# RZT2L register map
Vendor: Renesas Electronics Corporation; Series: RZT; File version: 1.20.00
CPU: other r0p0, little endian, MPU, no FPU, VTOR, 4 interrupt priority bits, 624 interrupts
Registers are 32-bit, read-write, reset 0x0 unless marked. A register's access mark holds for its fields unless they carry their own. Offsets are from the block's base; [hi:lo] are bit positions; {n}, {i} and the like mark numbered series; 'fields as' and 'values as' point back to an identical list.

## ICU — Interrupt Controller
Base 0x81048000
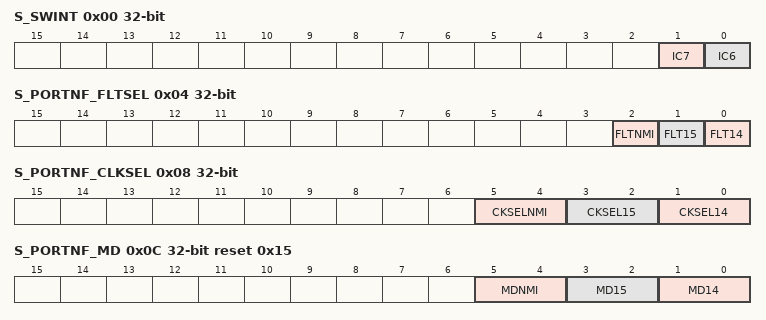
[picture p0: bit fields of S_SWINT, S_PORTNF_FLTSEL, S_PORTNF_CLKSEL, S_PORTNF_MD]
0x00 S_SWINT wo — Software Interrupt Register for Safety Register
  [1] IC7 — Software Interrupt register
  [0] IC6 — Software Interrupt register
0x04 S_PORTNF_FLTSEL — Interrupt Noise Filter Enable Register for Safety Register
  [all] fields
    0=Disable; 1=Enable
  [2] FLTNMI — Noise filter enable for NMI
  [1] FLT15 — Noise filter enable for IRQ15
  [0] FLT14 — Noise filter enable for IRQ14
0x08 S_PORTNF_CLKSEL — Interrupt Noise Filter Setting Register for Safety Register
  [all] fields
    0=Divided by 1; 1=Divided by 8; 2=Divided by 32; 3=Divided by 64
  [5:4] CKSELNMI — Select noise filter sampling frequency dividend rate for NMI.
  [3:2] CKSEL15 — Select noise filter sampling frequency dividend rate for IRQ15.
  [1:0] CKSEL14 — Select noise filter sampling frequency dividend rate for IRQ14.
0x0C S_PORTNF_MD reset 0x15 — Interrupt Edge Detection Setting Register for Safety Register
  [5:4] MDNMI — Select detection mode for NMI
    0=Invert; 1=Falling edge; 2=Rising edge; 3=Falling and rising edges
  [3:2] MD15 — Select detection mode for IRQ15
    0=Low level; 1=Falling edge; 2=Rising edge; 3=Falling and rising edges
  [1:0] MD14 — Select detection mode for IRQ14
    values as MD15
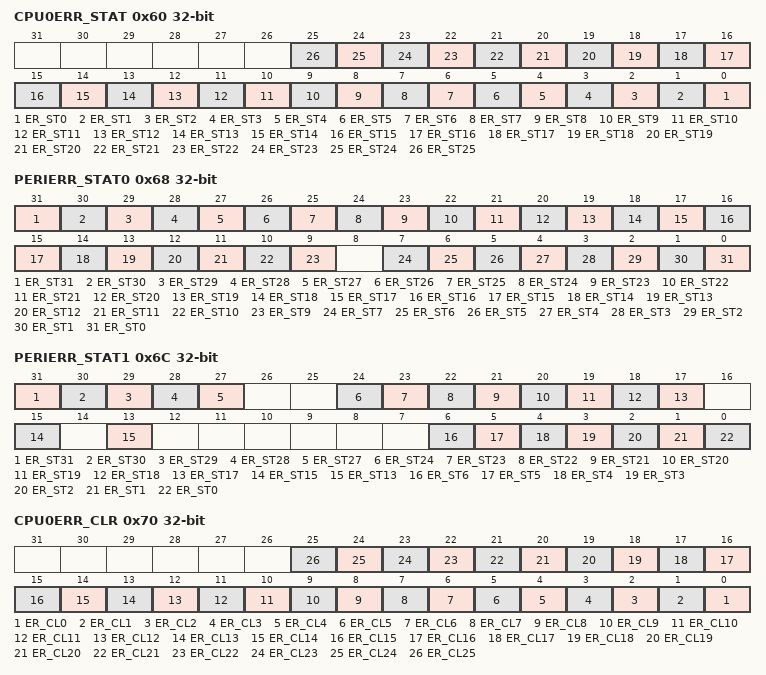
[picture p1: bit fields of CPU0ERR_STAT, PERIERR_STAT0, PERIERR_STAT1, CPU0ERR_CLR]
0x60 CPU0ERR_STAT ro — CPU0 Error Event Status Register
  [all] fields
    0=No error; 1=Error occurred
  [n] ER_ST{n} (n=0..25) — Indicate captured error status for CPU0_ERREVENT{n}
0x68 PERIERR_STAT0 ro — Peripheral Error Event Status Register 0
  [all] fields
    0=No error; 1=Error occurred
  [31] ER_ST31 — Indicate captured error status for DSMIF1_SCDE2
  [30] ER_ST30 — Indicate captured error status for DSMIF1_SCDE1
  [29] ER_ST29 — Indicate captured error status for DSMIF1_SCDE0
  [28] ER_ST28 — Indicate captured error status for DSMIF1_OVC2EHn (n = 0 to 2)
  [27] ER_ST27 — Indicate captured error status for DSMIF1_OVC1EHn (n = 0 to 2)
  [26] ER_ST26 — Indicate captured error status for DSMIF1_OVC0EHn (n = 0 to 2)
  [25] ER_ST25 — Indicate captured error status for DSMIF1_OVC2ELn (n = 0 to 2)
  [24] ER_ST24 — Indicate captured error status for DSMIF1_OVC1ELn (n = 0 to 2)
  [23] ER_ST23 — Indicate captured error status for DSMIF1_OVC0ELn (n = 0 to 2)
  [22] ER_ST22 — Indicate captured error status for DSMIF1_UTCSE
  [21] ER_ST21 — Indicate captured error status for DSMIF1_LTCSE
  [20] ER_ST20 — Indicate captured error status for DSMIF0_SCDE2
  [19] ER_ST19 — Indicate captured error status for DSMIF0_SCDE1
  [18] ER_ST18 — Indicate captured error status for DSMIF0_SCDE0
  [17] ER_ST17 — Indicate captured error status for DSMIF0_OVC2EHn (n = 0 to 2)
  [16] ER_ST16 — Indicate captured error status for DSMIF0_OVC1EHn (n = 0 to 2)
  [15] ER_ST15 — Indicate captured error status for DSMIF0_OVC0EHn (n = 0 to 2)
  [14] ER_ST14 — Indicate captured error status for DSMIF0_OVC2ELn (n = 0 to 2)
  [13] ER_ST13 — Indicate captured error status for DSMIF0_OVC1ELn (n = 0 to 2)
  [12] ER_ST12 — Indicate captured error status for DSMIF0_OVC0ELn (n = 0 to 2)
  [11] ER_ST11 — Indicate captured error status for DSMIF0_UTCSE
  [10] ER_ST10 — Indicate captured error status for DSMIF0_LTCSE
  [9] ER_ST9 — Indicate captured error status for USB_FDMAERR
  [7] ER_ST7 — Indicate captured error status for WDT_NMIUNDF0
  [6] ER_ST6 — Indicate captured error status for DMAC1_ERR
  [5] ER_ST5 — Indicate captured error status for DMAC0_ERR
  [4] ER_ST4 — Indicate captured error status for BSC_WTO
  [3] ER_ST3 — Indicate captured error status for CLMA2_INT
  [2] ER_ST2 — Indicate captured error status for CLMA1_INT
  [1] ER_ST1 — Indicate captured error status for CLMA0_INT
  [0] ER_ST0 — Indicate captured error status for CLMA3_INT
0x6C PERIERR_STAT1 ro — Peripheral Error Event Status Register 1
  [all] fields
    0=No error; 1=Error occurred
  [31] ER_ST31 — Indicate capture error status for DSMIF0_OVC2EL0
  [30] ER_ST30 — Indicate capture error status for DSMIF0_OVC1EH0
  [29] ER_ST29 — Indicate capture error status for DSMIF0_OVC1EL0
  [28] ER_ST28 — Indicate captured error status for MPU_DBGW
  [27] ER_ST27 — Indicate captured error status for MPU_DBGR
  [24] ER_ST24 — Indicate captured error status for MPU_USBF
  [23] ER_ST23 — Indicate captured error status for MPU_USBH
  [22] ER_ST22 — Indicate captured error status for MPU_GMACW
  [21] ER_ST21 — Indicate captured error status for MPU_GMACR
  [20] ER_ST20 — Indicate captured error status for MPU_DMACW1
  [19] ER_ST19 — Indicate captured error status for MPU_DMACR1
  [18] ER_ST18 — Indicate captured error status for MPU_DMACW0
  [17] ER_ST17 — Indicate captured error status for MPU_DMACR0
  [15] ER_ST15 — Indicate captured error status for MPU_SHOSTIF
  [13] ER_ST13 — Indicate captured error status for MAIN_BUS_ERRINT
  [6] ER_ST6 — Indicate captured error status for SRAM1_OVF
  [5] ER_ST5 — Indicate captured error status for SRAM1_IE2
  [4] ER_ST4 — Indicate captured error status for SRAM1_IE1
  [3] ER_ST3 — Indicate captured error status for SRAM0_OVF
  [2] ER_ST2 — Indicate captured error status for SRAM0_IE2
  [1] ER_ST1 — Indicate captured error status for SRAM0_IE1
  [0] ER_ST0 — Indicate captured error status for DOC_DOPCI
0x70 CPU0ERR_CLR wo — CPU0 Error Event Status Clear Register
  [n] ER_CL{n} (n=0..25) — Clear captured error status for CPU0ERR_STAT register by writing 1
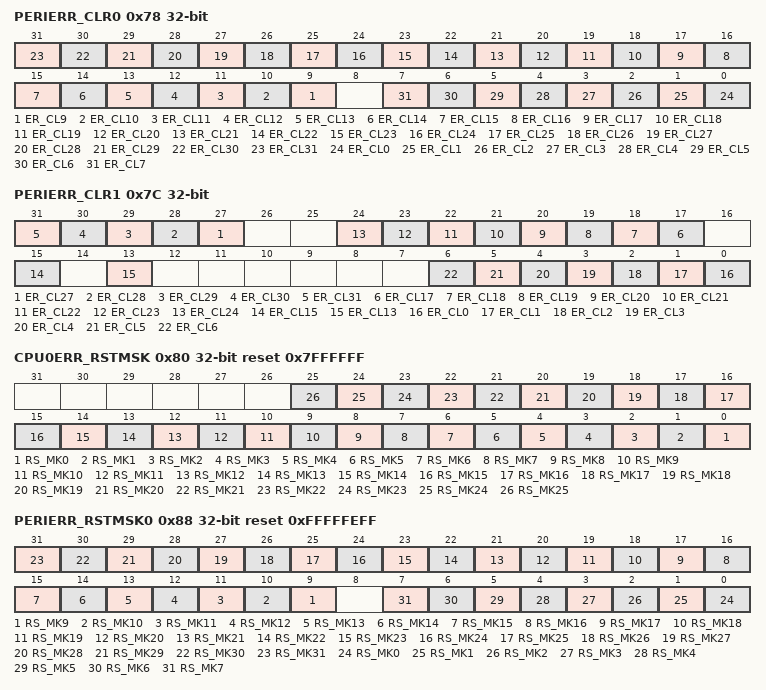
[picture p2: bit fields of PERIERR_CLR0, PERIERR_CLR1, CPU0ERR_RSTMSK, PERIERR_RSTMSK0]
0x78 PERIERR_CLR0 wo — Peripheral Error Event Status Clear Register 0
  [n] ER_CL{n} (n=9..31) — Clear captured error status for PERIERR_STAT0 register by writing 1
  [n] ER_CL{n} (n=0..7) — Clear captured error status for PERIERR_STAT0 register by writing 1
0x7C PERIERR_CLR1 wo — Peripheral Error Event Status Clear Register 1
  [n] ER_CL{n} (n=27..31) — Clear captured error status for PERIERR_STAT1 register by writing 1
  [n] ER_CL{n} (n=17..24) — Clear captured error status for PERIERR_STAT1 register by writing 1
  [15] ER_CL15 — Clear captured error status for PERIERR_STAT1 register by writing 1
  [13] ER_CL13 — Clear captured error status for PERIERR_STAT1 register by writing 1
  [n] ER_CL{n} (n=0..6) — Clear captured error status for PERIERR_STAT1 register by writing 1
0x80 CPU0ERR_RSTMSK reset 0x7FFFFFF — CPU0 Error Event Reset Mask Register
  [all] fields
    0=Release; 1=Mask
  [n] RS_MK{n} (n=0..25) — Mask captured error status as a reset event for CPU0ERR_STAT
0x88 PERIERR_RSTMSK0 reset 0xFFFFFEFF — Peripheral Error Event Reset Mask Register 0
  [all] fields
    0=Release; 1=Mask
  [n] RS_MK{n} (n=9..31) — Mask captured error status as a reset event for PERIERR_STAT0
  [n] RS_MK{n} (n=0..7) — Mask captured error status as a reset event for PERIERR_STAT0
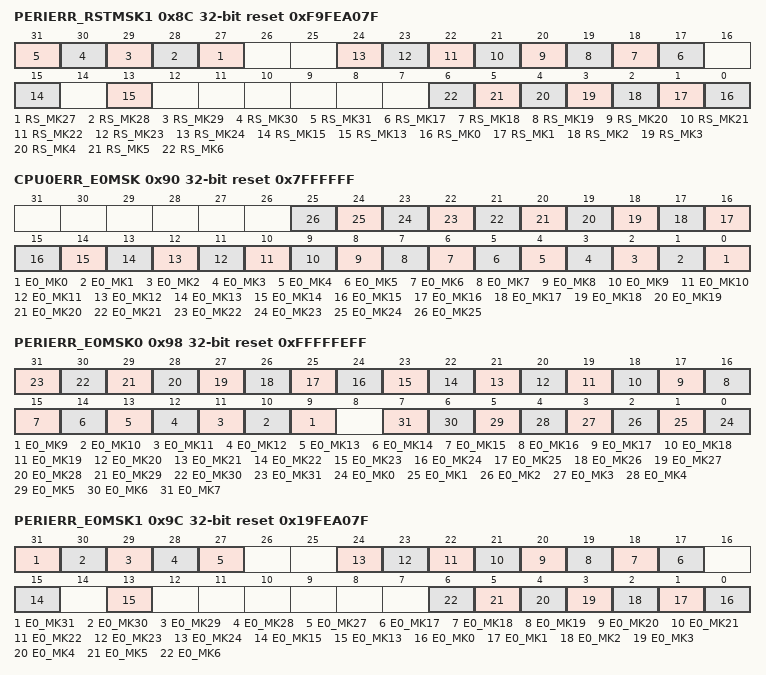
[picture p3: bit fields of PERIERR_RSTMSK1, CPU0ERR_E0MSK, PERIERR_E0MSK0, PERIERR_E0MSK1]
0x8C PERIERR_RSTMSK1 reset 0xF9FEA07F — Peripheral Error Event Reset Mask Register 1
  [all] fields
    0=Release; 1=Mask
  [n] RS_MK{n} (n=27..31) — Mask captured error status as a reset event for PERIERR_STAT1
  [n] RS_MK{n} (n=17..24) — Mask captured error status as a reset event for PERIERR_STAT1
  [15] RS_MK15 — Mask captured error status as a reset event for PERIERR_STAT1
  [13] RS_MK13 — Mask captured error status as a reset event for PERIERR_STAT1
  [n] RS_MK{n} (n=0..6) — Mask captured error status as a reset event for PERIERR_STAT1
0x90 CPU0ERR_E0MSK reset 0x7FFFFFF — CPU0 E0 Error Event Mask Register
  [all] fields
    0=Release; 1=Mask
  [n] E0_MK{n} (n=0..25) — Mask captured error status as a CPU0_ERR0 event for CPU0ERR_STAT
0x98 PERIERR_E0MSK0 reset 0xFFFFFEFF — Peripheral E0 Error Event Mask Register 0
  [all] fields
    0=Release; 1=Mask
  [n] E0_MK{n} (n=9..31) — Mask captured error status as a PERI_ERR0 event for PERIERR_STAT0
  [n] E0_MK{n} (n=0..7) — Mask captured error status as a PERI_ERR0 event for PERIERR_STAT0
0x9C PERIERR_E0MSK1 reset 0x19FEA07F — Peripheral E0 Error Event Mask Register 1
  [all] fields
    0=Release; 1=Mask
  [31] E0_MK31 — Mask captured error status as a PERI_ERR0 event for PERIERR_STAT1
  [30] E0_MK30 — Mask captured error status as a PERI_ERR0 event for PERIERR_STAT1
  [29] E0_MK29 — Mask capture error status as a PERI_ERR0 event for PERIERR_STAT1
  [28] E0_MK28 — Mask captured error status as a PERI_ERR0 event for PERIERR_STAT1
  [27] E0_MK27 — Mask captured error status as a PERI_ERR0 event for PERIERR_STAT1
  [n] E0_MK{n} (n=17..24) — Mask captured error status as a PERI_ERR0 event for PERIERR_STAT1
  [15] E0_MK15 — Mask captured error status as a PERI_ERR0 event for PERIERR_STAT1
  [13] E0_MK13 — Mask captured error status as a PERI_ERR0 event for PERIERR_STAT1
  [n] E0_MK{n} (n=0..6) — Mask captured error status as a PERI_ERR0 event for PERIERR_STAT1
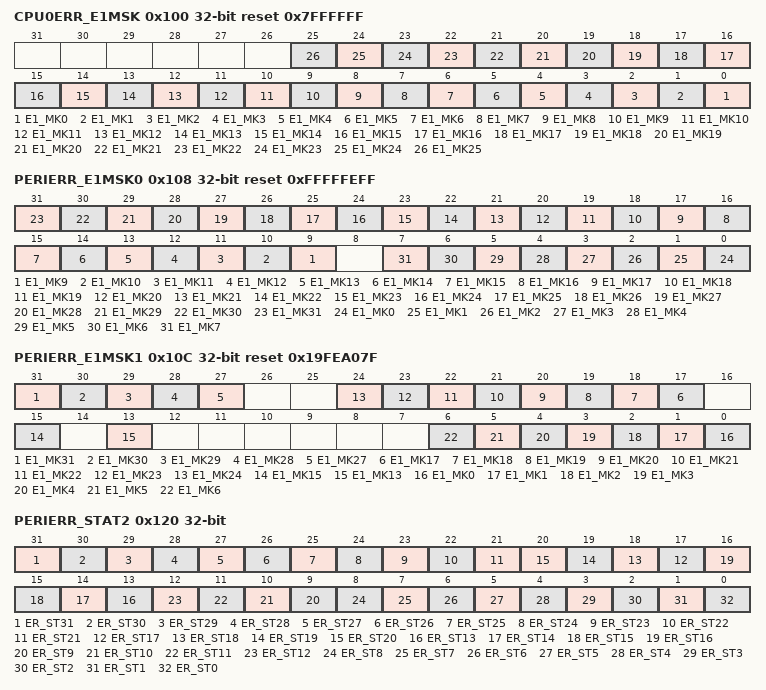
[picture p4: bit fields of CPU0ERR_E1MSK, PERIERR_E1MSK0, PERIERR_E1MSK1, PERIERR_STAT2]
0x100 CPU0ERR_E1MSK reset 0x7FFFFFF — CPU0 E1 Error Event Mask Register
  [all] fields
    0=Release; 1=Mask
  [n] E1_MK{n} (n=0..25) — Mask captured error status as a CPU0_ERR1 event for CPU0ERR_STAT
0x108 PERIERR_E1MSK0 reset 0xFFFFFEFF — Peripheral E1 Error Event Mask Register 0
  [all] fields
    0=Release; 1=Mask
  [n] E1_MK{n} (n=9..31) — Mask captured error status as a PERI_ERR1 event for PERIERR_STAT0
  [n] E1_MK{n} (n=0..7) — Mask captured error status as a PERI_ERR1 event for PERIERR_STAT0
0x10C PERIERR_E1MSK1 reset 0x19FEA07F — Peripheral E1 Error Event Mask Register 1
  [all] fields
    0=Release; 1=Mask
  [31] E1_MK31 — Mask capture error status as a PERI_ERR1 event for PERIERR_STAT1
  [30] E1_MK30 — Mask capture error status as a PERI_ERR1 event for PERIERR_STAT1
  [29] E1_MK29 — Mask capture error status as a PERI_ERR1 event for PERIERR_STAT1
  [28] E1_MK28 — Mask captured error status as a PERI_ERR1 event for PERIERR_STAT1
  [27] E1_MK27 — Mask captured error status as a PERI_ERR1 event for PERIERR_STAT1
  [n] E1_MK{n} (n=17..24) — Mask captured error status as a PERI_ERR1 event for PERIERR_STAT1
  [15] E1_MK15 — Mask captured error status as a PERI_ERR1 event for PERIERR_STAT1
  [13] E1_MK13 — Mask captured error status as a PERI_ERR1 event for PERIERR_STAT1
  [n] E1_MK{n} (n=0..6) — Mask captured error status as a PERI_ERR1 event for PERIERR_STAT1
0x120 PERIERR_STAT2 ro — Peripheral Error Event Status Register 2
  [all] fields
    0=No error; 1=Error occurred
  [31] ER_ST31 — Indicate capture error status for DSMIF1_OVC2EL2
  [30] ER_ST30 — Indicate capture error status for DSMIF1_OVC1EH2
  [29] ER_ST29 — Indicate capture error status for DSMIF1_OVC1EL2
  [28] ER_ST28 — Indicate capture error status for DSMIF1_OVC2EH1
  [27] ER_ST27 — Indicate capture error status for DSMIF1_OVC2EL1
  [26] ER_ST26 — Indicate capture error status for DSMIF1_OVC1EH1
  [25] ER_ST25 — Indicate capture error status for DSMIF1_OVC1EL1
  [24] ER_ST24 — Indicate capture error status for DSMIF1_OVC2EH0
  [23] ER_ST23 — Indicate capture error status for DSMIF1_OVC2EL0
  [22] ER_ST22 — Indicate capture error status for DSMIF1_OVC1EH0
  [21] ER_ST21 — Indicate capture error status for DSMIF1_OVC1EL0
  [n] ER_ST{n} (n=17..20) — Indicate capture error status for DSMIF0_OVC{n-17}WN2
  [n] ER_ST{n} (n=13..16) — Indicate capture error status for DSMIF0_OVC{n-13}WN1
  [n] ER_ST{n} (n=9..12) — Indicate capture error status for DSMIF0_OVC{n-9}WN0
  [8] ER_ST8 — Indicate capture error status for DSMIF0_OVC2EH2
  [7] ER_ST7 — Indicate capture error status for DSMIF0_OVC2EL2
  [6] ER_ST6 — Indicate capture error status for DSMIF0_OVC1EH2
  [5] ER_ST5 — Indicate capture error status for DSMIF0_OVC1EL2
  [4] ER_ST4 — Indicate capture error status for DSMIF0_OVC2EH1
  [3] ER_ST3 — Indicate capture error status for DSMIF0_OVC2EL1
  [2] ER_ST2 — Indicate capture error status for DSMIF0_OVC1EH1
  [1] ER_ST1 — Indicate capture error status for DSMIF0_OVC1EL1
  [0] ER_ST0 — Indicate capture error status for DSMIF0_OVC2EH0
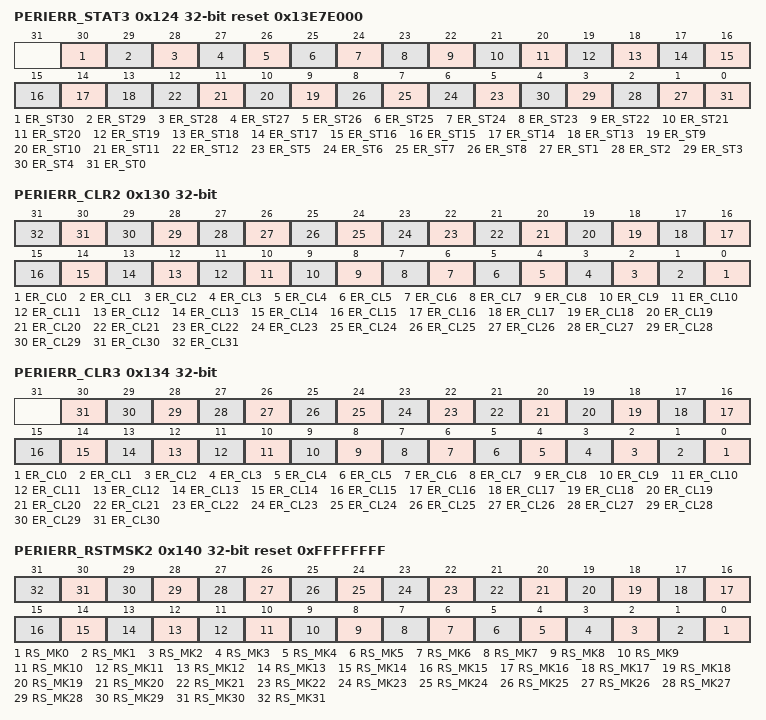
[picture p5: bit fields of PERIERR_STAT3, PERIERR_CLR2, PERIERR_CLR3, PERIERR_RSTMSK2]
0x124 PERIERR_STAT3 ro reset 0x13E7E000 — Peripheral Error Event Status Register 3
  [all] fields
    0=No error; 1=Error occurred
  [30] ER_ST30 — Indicate capture error status for AFMT1_TMOUT
  [29] ER_ST29 — Indicate capture error status for AFMT0_TMOUT
  [28] ER_ST28 — Indicate capture error status for HDSL1_dev_thr_err
  [27] ER_ST27 — Indicate capture error status for HDSL1_encoding_err
  [26] ER_ST26 — Indicate capture error status for HDSL1_acc_thr_err
  [25] ER_ST25 — Indicate capture error status for HDSL1_acceleration_err
  [24] ER_ST24 — Indicate capture error status for HDSL1_safe_pos_err
  [23] ER_ST23 — Indicate capture error status for HDSL1_safe_channel_err
  [22] ER_ST22 — Indicate capture error status for HDSL1_estimator_on
  [21] ER_ST21 — Indicate capture error status for HDSL0_dev_thr_err
  [20] ER_ST20 — Indicate capture error status for HDSL0_encoding_err
  [19] ER_ST19 — Indicate capture error status for HDSL0_acc_thr_err
  [18] ER_ST18 — Indicate capture error status for HDSL0_acceleration_err
  [17] ER_ST17 — Indicate capture error status for HDSL0_safe_pos_err
  [16] ER_ST16 — Indicate capture error status for HDSL0_safe_channel_err
  [15] ER_ST15 — Indicate capture error status for HDSL0_estimator_on
  [14] ER_ST14 — Indicate capture error status for BISS1_NER
  [13] ER_ST13 — Indicate capture error status for BISS0_NER
  [n] ER_ST{n} (n=9..12) — Indicate capture error status for DSMIF1_OVC{n-9}WN2
  [n] ER_ST{n} (n=5..8) — Indicate capture error status for DSMIF1_OVC{n-5}WN1
  [n] ER_ST{n} (n=1..4) — Indicate capture error status for DSMIF1_OVC{n-1}WN0
  [0] ER_ST0 — Indicate capture error status for DSMIF1_OVC2EH2
0x130 PERIERR_CLR2 wo — Peripheral Error Event Status Clear Register 2
  [n] ER_CL{n} (n=0..31)
0x134 PERIERR_CLR3 wo — Peripheral Error Event Status Clear Register 3
  [n] ER_CL{n} (n=0..30)
0x140 PERIERR_RSTMSK2 reset 0xFFFFFFFF — Peripheral Error Event Reset Mask Register 2
  [all] fields
    0=Release; 1=Mask
  [n] RS_MK{n} (n=0..31) — Mask captured error status as a reset event for PERIERR_STAT2
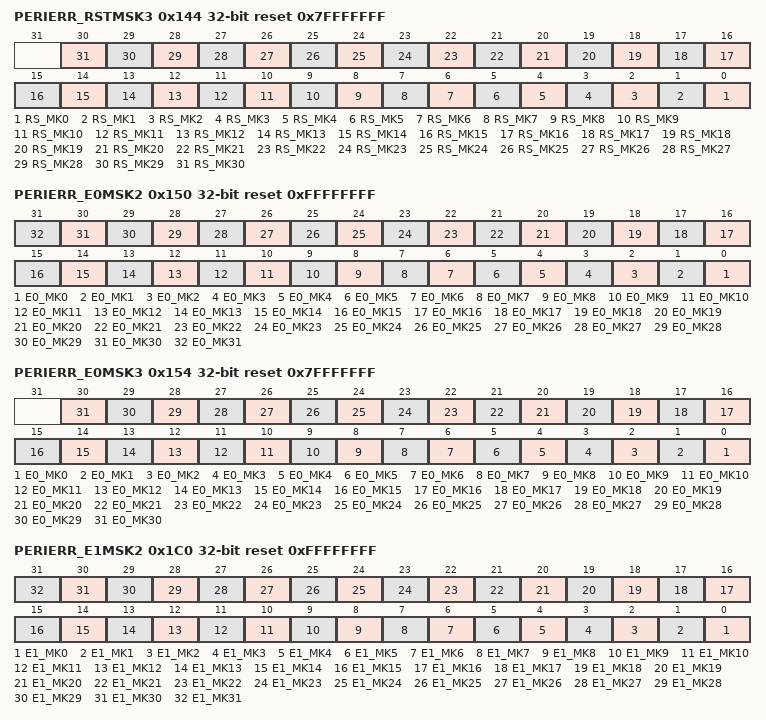
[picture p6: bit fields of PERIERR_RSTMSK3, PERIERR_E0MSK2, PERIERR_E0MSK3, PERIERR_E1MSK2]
0x144 PERIERR_RSTMSK3 reset 0x7FFFFFFF — Peripheral Error Event Reset Mask Register 3
  [all] fields
    0=Release; 1=Mask
  [n] RS_MK{n} (n=0..30) — Mask captured error status as a reset event for PERIERR_STAT3
0x150 PERIERR_E0MSK2 reset 0xFFFFFFFF — Peripheral E0 Error Event Mask Register 2
  [all] fields
    0=Release; 1=Mask
  [n] E0_MK{n} (n=0..31) — Mask captured error status as a PERI_ERR0 event for PERIERR_STAT2
0x154 PERIERR_E0MSK3 reset 0x7FFFFFFF — Peripheral E0 Error Event Mask Register 3
  [all] fields
    0=Release; 1=Mask
  [n] E0_MK{n} (n=0..30) — Mask captured error status as a PERI_ERR0 event for PERIERR_STAT3
0x1C0 PERIERR_E1MSK2 reset 0xFFFFFFFF — Peripheral E1 Error Event Mask Register 2
  [all] fields
    0=Release; 1=Mask
  [n] E1_MK{n} (n=0..31) — Mask captured error status as a PERI_ERR1 event for PERIERR_STAT2
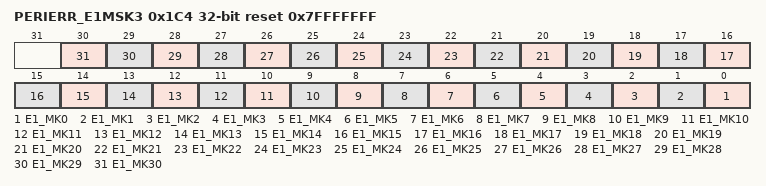
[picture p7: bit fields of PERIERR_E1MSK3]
0x1C4 PERIERR_E1MSK3 reset 0x7FFFFFFF — Peripheral E1 Error Event Mask Register 3
  [all] fields
    0=Release; 1=Mask
  [n] E1_MK{n} (n=0..30) — Mask captured error status as a PERI_ERR1 event for PERIERR_STAT3
